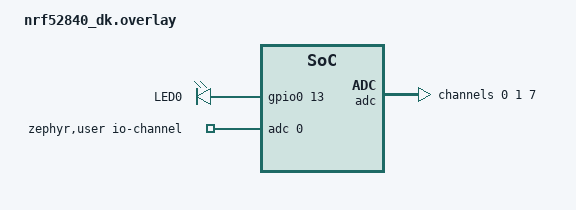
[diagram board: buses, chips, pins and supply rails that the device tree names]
// To get started, press Ctrl+Space to bring up the completion menu and view the available nodes.

// You can also use the buttons in the sidebar to perform actions on nodes.
// Actions currently available include:

// * Enabling / disabling the node
// * Adding the bus to a bus
// * Removing the node
// * Connecting ADC channels

// For more help, browse the DeviceTree documentation at https://docs.zephyrproject.org/latest/guides/dts/index.html
// You can also visit the nRF DeviceTree extension documentation at https://docs.nordicsemi.com/bundle/nrf-connect-vscode/page/guides/ncs_configure_app.html#devicetree-support-in-the-extension

/ {
	leds {
		compatible = "gpio-leds";
		led0: led0 {
			gpios = <&gpio0 13 0>;
			label = "LED0";
		};
	};
	zephyr,user {
		io-channels = <&adc 0>;
	};
};

&adc {
	#address-cells = <1>;
	#size-cells = <0>;

	channel@0 {
		reg = <0>;
		zephyr,gain = "ADC_GAIN_1_6";
		zephyr,reference = "ADC_REF_INTERNAL";
		zephyr,acquisition-time = <ADC_ACQ_TIME_DEFAULT>;
		zephyr,input-positive = <NRF_SAADC_AIN1>; /* P0.03 */
		zephyr,resolution = <12>;
	};

	channel@1 {
		reg = <1>;
		zephyr,gain = "ADC_GAIN_1_6";
		zephyr,reference = "ADC_REF_INTERNAL";
		zephyr,acquisition-time = <ADC_ACQ_TIME_DEFAULT>;
		zephyr,input-positive = <NRF_SAADC_VDD>;
		zephyr,resolution = <14>;
		zephyr,oversampling = <8>;
	};

	channel@7 {
		reg = <7>;
		zephyr,gain = "ADC_GAIN_1_5";
		zephyr,reference = "ADC_REF_VDD_1_4";
		zephyr,vref-mv = <750>;
		zephyr,acquisition-time = <ADC_ACQ_TIME_DEFAULT>;
		zephyr,input-positive = <NRF_SAADC_AIN6>; /* P0.30 */
		zephyr,input-negative = <NRF_SAADC_AIN7>; /* P0.31 */
		zephyr,resolution = <12>;
	};
};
